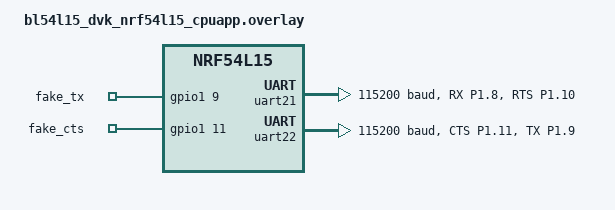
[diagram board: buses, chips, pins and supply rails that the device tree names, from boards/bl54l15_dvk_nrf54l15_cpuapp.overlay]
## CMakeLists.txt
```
# SPDX-License-Identifier: Apache-2.0

cmake_minimum_required(VERSION 3.28.0)

find_package(Zephyr REQUIRED HINTS $ENV{ZEPHYR_BASE})
project(uart_errors)

target_sources(app PRIVATE
    src/uart_errors_common.c
    src/test_parity.c
    src/test_stop_bit.c
    )
```

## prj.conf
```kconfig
CONFIG_SERIAL=y
CONFIG_GPIO=y
CONFIG_ZTEST=y
CONFIG_TEST_USERSPACE=y
CONFIG_UART_USE_RUNTIME_CONFIGURE=y
CONFIG_UART_INTERRUPT_DRIVEN=y
CONFIG_PM_DEVICE=y
```

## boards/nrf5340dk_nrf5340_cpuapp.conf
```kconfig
CONFIG_TIMING_FUNCTIONS=y
```

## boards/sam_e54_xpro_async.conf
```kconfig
CONFIG_DMA=y
```

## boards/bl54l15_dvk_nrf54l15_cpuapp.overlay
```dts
/*
 * Copyright (c) 2024 Nordic Semiconductor ASA
 * Copyright (c) 2025 Ezurio LLC
 *
 * SPDX-License-Identifier: Apache-2.0
 */

&pinctrl {
	uart21_default: uart21_default {
		group1 {
			psels = <NRF_PSEL(UART_RX, 1, 8)>,
				<NRF_PSEL(UART_RTS, 1, 10)>;
		};
	};

	uart21_sleep: uart21_sleep {
		group1 {
			psels = <NRF_PSEL(UART_RX, 1, 8)>,
				<NRF_PSEL(UART_RTS, 1, 10)>;
			low-power-enable;
		};
	};

	uart22_default: uart22_default {
		group1 {
			psels = <NRF_PSEL(UART_CTS, 1, 11)>;
			bias-pull-up;
		};

		group2 {
			psels = <NRF_PSEL(UART_TX, 1, 9)>;
		};
	};

	uart22_sleep: uart22_sleep {
		group1 {
			psels = <NRF_PSEL(UART_TX, 1, 9)>,
				<NRF_PSEL(UART_CTS, 1, 11)>;
			low-power-enable;
		};
	};
};

dut: &uart21 {
	current-speed = <115200>;
	pinctrl-0 = <&uart21_default>;
	pinctrl-1 = <&uart21_sleep>;
	pinctrl-names = "default", "sleep";
	status = "okay";
};

dut_aux: &uart22 {
	current-speed = <115200>;
	pinctrl-0 = <&uart22_default>;
	pinctrl-1 = <&uart22_sleep>;
	pinctrl-names = "default", "sleep";
	disable-rx;
	status = "okay";
};

/ {
	fake_uart {
		compatible = "gpio-keys";

		fake_tx: fake_tx {
			gpios = <&gpio1 9 GPIO_ACTIVE_HIGH>;
		};

		fake_cts: fake_cts {
			gpios = <&gpio1 11 GPIO_ACTIVE_HIGH>;
		};
	};
};
```

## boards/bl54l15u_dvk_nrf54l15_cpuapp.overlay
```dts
/*
 * Copyright (c) 2024 Nordic Semiconductor ASA
 * Copyright (c) 2025 Ezurio LLC
 *
 * SPDX-License-Identifier: Apache-2.0
 */

&pinctrl {
	uart21_default: uart21_default {
		group1 {
			psels = <NRF_PSEL(UART_RX, 1, 8)>,
				<NRF_PSEL(UART_RTS, 1, 10)>;
		};
	};

	uart21_sleep: uart21_sleep {
		group1 {
			psels = <NRF_PSEL(UART_RX, 1, 8)>,
				<NRF_PSEL(UART_RTS, 1, 10)>;
			low-power-enable;
		};
	};

	uart22_default: uart22_default {
		group1 {
			psels = <NRF_PSEL(UART_CTS, 1, 11)>;
			bias-pull-up;
		};

		group2 {
			psels = <NRF_PSEL(UART_TX, 1, 9)>;
		};
	};

	uart22_sleep: uart22_sleep {
		group1 {
			psels = <NRF_PSEL(UART_TX, 1, 9)>,
				<NRF_PSEL(UART_CTS, 1, 11)>;
			low-power-enable;
		};
	};
};

dut: &uart21 {
	status = "okay";
	current-speed = <115200>;
	pinctrl-0 = <&uart21_default>;
	pinctrl-1 = <&uart21_sleep>;
	pinctrl-names = "default", "sleep";
};

dut_aux: &uart22 {
	status = "okay";
	current-speed = <115200>;
	pinctrl-0 = <&uart22_default>;
	pinctrl-1 = <&uart22_sleep>;
	pinctrl-names = "default", "sleep";
	disable-rx;
};

/ {
	fake_uart {
		compatible = "gpio-keys";

		fake_tx: fake_tx {
			gpios = <&gpio1 9 GPIO_ACTIVE_HIGH>;
		};

		fake_cts: fake_cts {
			gpios = <&gpio1 11 GPIO_ACTIVE_HIGH>;
		};
	};
};
```

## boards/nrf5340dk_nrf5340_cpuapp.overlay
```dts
/* SPDX-License-Identifier: Apache-2.0 */

&pinctrl {
	uart1_default_alt: uart1_default_alt {
		group1 {
			psels = <NRF_PSEL(UART_RX, 0, 4)>;
			bias-pull-up;
		};

		group2 {
			psels = <NRF_PSEL(UART_RTS, 0, 6)>;
		};
	};

	uart1_sleep_alt: uart1_sleep_alt {
		group1 {
			psels = <NRF_PSEL(UART_RX, 0, 4)>,
				<NRF_PSEL(UART_RTS, 0, 6)>;
			low-power-enable;
		};
	};

	uart2_default_alt: uart2_default_alt {
		group1 {
			psels = <NRF_PSEL(UART_TX, 0, 5)>;
		};

		group2 {
			psels = <NRF_PSEL(UART_CTS, 0, 7)>;
			bias-pull-up;
		};
	};

	uart2_sleep_alt: uart2_sleep_alt {
		group1 {
			psels = <NRF_PSEL(UART_TX, 0, 5)>,
				<NRF_PSEL(UART_CTS, 0, 7)>;
			low-power-enable;
		};
	};
};

dut: &uart1 {
	compatible = "nordic,nrf-uarte";
	current-speed = <115200>;
	pinctrl-0 = <&uart1_default_alt>;
	pinctrl-1 = <&uart1_sleep_alt>;
	pinctrl-names = "default", "sleep";
	status = "okay";
};

dut_aux: &uart2 {
	compatible = "nordic,nrf-uarte";
	current-speed = <115200>;
	pinctrl-0 = <&uart2_default_alt>;
	pinctrl-1 = <&uart2_sleep_alt>;
	pinctrl-names = "default", "sleep";
	disable-rx;
	status = "okay";
};

/ {
	fake_uart {
		compatible = "gpio-keys";

		fake_tx: fake_tx {
			gpios = <&gpio0 5 GPIO_ACTIVE_HIGH>;
		};

		fake_cts: fake_cts {
			gpios = <&gpio0 7 GPIO_ACTIVE_HIGH>;
		};
	};
};
```

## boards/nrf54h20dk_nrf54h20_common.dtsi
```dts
/* SPDX-License-Identifier: Apache-2.0 */

&pinctrl {
	uart135_default_alt: uart135_default_alt {
		group1 {
			psels = <NRF_PSEL(UART_RX, 0, 6)>;
			bias-pull-up;
		};

		group2 {
			psels = <NRF_PSEL(UART_RTS, 0, 8)>;
		};
	};

	uart135_sleep_alt: uart135_sleep_alt {
		group1 {
			psels = <NRF_PSEL(UART_RX, 0, 6)>,
				<NRF_PSEL(UART_RTS, 0, 8)>;
			low-power-enable;
		};
	};
};

&pinctrl {
	uart137_default_alt: uart137_default_alt {
		group1 {
			psels = <NRF_PSEL(UART_TX, 0, 7)>;
		};

		group2 {
			psels = <NRF_PSEL(UART_CTS, 0, 9)>;
			bias-pull-up;
		};
	};

	uart137_sleep_alt: uart137_sleep_alt {
		group1 {
			psels = <NRF_PSEL(UART_TX, 0, 7)>,
				<NRF_PSEL(UART_CTS, 0, 9)>;
			low-power-enable;
		};
	};
};

&gpio0 {
	status = "okay";
};

dut: &uart135 {
	memory-regions = <&cpuapp_dma_region>;
	pinctrl-0 = <&uart135_default_alt>;
	pinctrl-1 = <&uart135_sleep_alt>;
	pinctrl-names = "default", "sleep";
	current-speed = <115200>;
	status = "okay";
};

dut_aux: &uart137 {
	memory-regions = <&cpuapp_dma_region>;
	pinctrl-0 = <&uart137_default_alt>;
	pinctrl-1 = <&uart137_sleep_alt>;
	pinctrl-names = "default", "sleep";
	current-speed = <115200>;
	disable-rx;
	status = "okay";
};

/ {
	fake_uart {
		compatible = "gpio-keys";

		fake_tx: fake_tx {
			gpios = <&gpio0 7 GPIO_ACTIVE_HIGH>;
		};

		fake_cts: fake_cts {
			gpios = <&gpio0 9 GPIO_ACTIVE_HIGH>;
		};
	};
};
```

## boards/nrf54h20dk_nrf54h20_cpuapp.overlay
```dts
/* SPDX-License-Identifier: Apache-2.0 */

#include "nrf54h20dk_nrf54h20_common.dtsi"

&dut_aux {
	memory-regions = <&cpuapp_dma_region>;
};

&dut {
	memory-regions = <&cpuapp_dma_region>;
};
```

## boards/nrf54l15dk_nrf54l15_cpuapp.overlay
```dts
/*
 * Copyright (c) 2025 Nordic Semiconductor ASA
 *
 * SPDX-License-Identifier: Apache-2.0
 */

&pinctrl {
	uart21_default: uart21_default {
		group1 {
			psels = <NRF_PSEL(UART_RX, 1, 8)>;
			bias-pull-up;
		};

		group2 {
			psels = <NRF_PSEL(UART_RTS, 1, 10)>;
		};
	};

	uart21_sleep: uart21_sleep {
		group1 {
			psels = <NRF_PSEL(UART_RX, 1, 8)>,
				<NRF_PSEL(UART_RTS, 1, 10)>;
			low-power-enable;
		};
	};

	uart22_default: uart22_default {
		group1 {
			psels = <NRF_PSEL(UART_CTS, 1, 11)>;
			bias-pull-up;
		};

		group2 {
			psels = <NRF_PSEL(UART_TX, 1, 9)>;
		};
	};

	uart22_sleep: uart22_sleep {
		group1 {
			psels = <NRF_PSEL(UART_CTS, 1, 11)>;
			low-power-enable;
		};
	};
};

dut: &uart21 {
	current-speed = <115200>;
	pinctrl-0 = <&uart21_default>;
	pinctrl-1 = <&uart21_sleep>;
	pinctrl-names = "default", "sleep";
	status = "okay";
};

dut_aux: &uart22 {
	current-speed = <115200>;
	pinctrl-0 = <&uart22_default>;
	pinctrl-1 = <&uart22_sleep>;
	pinctrl-names = "default", "sleep";
	disable-rx;
	status = "okay";
};

/ {
	fake_uart {
		compatible = "gpio-keys";

		fake_tx: fake_tx {
			gpios = <&gpio1 9 GPIO_ACTIVE_HIGH>;
		};

		fake_cts: fake_cts {
			gpios = <&gpio1 11 GPIO_ACTIVE_HIGH>;
		};
	};
};
```

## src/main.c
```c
/*
 * Copyright (c) 2024 Nordic Semiconductor ASA
 *
 * SPDX-License-Identifier: Apache-2.0
 */

/**
 * @addtogroup t_driver_uart
 * @{
 * @defgroup t_uart_errors test_uart_errors
 * @}
 */

#include <zephyr/drivers/uart.h>
#include <zephyr/pm/device.h>
#include <zephyr/pm/device_runtime.h>
#include <zephyr/ztest.h>
#include <zephyr/logging/log.h>
LOG_MODULE_REGISTER(test, LOG_LEVEL_NONE);

#if DT_NODE_EXISTS(DT_NODELABEL(dut))
#define UART_NODE DT_NODELABEL(dut)
#else
#error "No dut device in the test"
#endif

#if DT_NODE_EXISTS(DT_NODELABEL(dut_aux))
#define UART_NODE_AUX DT_NODELABEL(dut_aux)
#else
#error "No dut_aux device in the test"
#endif

static const struct device *const uart_dev = DEVICE_DT_GET(UART_NODE);
static const struct device *const uart_dev_aux = DEVICE_DT_GET(UART_NODE_AUX);

#define RX_CHUNK_CNT 2
#define RX_CHUNK_LEN 16
#define RX_TIMEOUT (1 * USEC_PER_MSEC)

static uint8_t rx_chunks[RX_CHUNK_CNT][16];
static uint32_t rx_chunks_mask = BIT_MASK(RX_CHUNK_CNT);
static uint8_t rx_buffer[256];
static uint32_t rx_buffer_cnt;
static volatile uint32_t rx_error_cnt;
static volatile bool rx_active;

struct aux_dut_data {
	const uint8_t *buf;
	size_t len;
	size_t curr;
	int err_byte;
	struct k_sem *sem;
	bool cfg_ok;
};

/* Simple buffer allocator. If allocation fails then test fails inside that function. */
static uint8_t *alloc_rx_chunk(void)
{
	uint32_t idx;

	zassert_true(rx_chunks_mask > 0);

	idx = __builtin_ctz(rx_chunks_mask);
	rx_chunks_mask &= ~BIT(idx);

	return rx_chunks[idx];
}

static void free_rx_chunk(uint8_t *buf)
{
	memset(buf, 0, RX_CHUNK_LEN);
	for (size_t i = 0; i < ARRAY_SIZE(rx_chunks); i++) {
		if (rx_chunks[i] == buf) {
			rx_chunks_mask |= BIT(i);
			break;
		}
	}
}

static void dut_async_callback(const struct device *dev, struct uart_event *evt, void *user_data)
{
	switch (evt->type) {
	case UART_TX_DONE:
		zassert_true(false);
		break;
	case UART_RX_RDY:
		LOG_INF("RX:%p len:%d off:%d",
			(void *)evt->data.rx.buf, evt->data.rx.len, evt->data.rx.offset);
		/* Aggregate all received data into a single buffer. */
		memcpy(&rx_buffer[rx_buffer_cnt], &evt->data.rx.buf[evt->data.rx.offset],
			evt->data.rx.len);
		rx_buffer_cnt += evt->data.rx.len;
		break;
	case UART_RX_BUF_REQUEST:
	{
		uint8_t *buf = alloc_rx_chunk();

		LOG_INF("buf request: %p", (void *)buf);
		zassert_equal(uart_rx_buf_rsp(dev, buf, RX_CHUNK_LEN), 0);
		break;
	}
	case UART_RX_BUF_RELEASED:
		LOG_INF("buf release: %p", (void *)evt->data.rx_buf.buf);
		free_rx_chunk(evt->data.rx_buf.buf);
		break;
	case UART_RX_DISABLED:
		zassert_true(rx_chunks_mask == BIT_MASK(RX_CHUNK_CNT));
		/* If test continues re-enable the receiver. Disabling may happen
		 * during the test after error is detected.
		 */
		if (rx_active) {
			uint8_t *buf = alloc_rx_chunk();
			int err;

			LOG_INF("RX disabled, re-enabling:%p", (void *)buf);
			err = uart_rx_enable(dev, buf, RX_CHUNK_LEN, RX_TIMEOUT);
			zassert_equal(err, 0);
		} else {
			LOG_WRN("RX disabled");
		}
		break;
	case UART_RX_ERROR:
		LOG_WRN("RX error");
		rx_error_cnt++;
		(void)uart_rx_disable(dev);
		break;
	default:
		zassert_true(false);
		break;
	}

}

static void dut_int_callback(const struct device *dev, void *user_data)
{
	while (true) {
		uart_irq_update(dev);

		if (uart_irq_is_pending(dev) <= 0) {
			break;
		}

		zassert_false(uart_irq_tx_ready(dev));
		if (uart_err_check(dev) != 0) {
			rx_error_cnt++;
		}
		if (uart_irq_rx_ready(dev)) {
			size_t rem = sizeof(rx_buffer) - rx_buffer_cnt;
			int len = uart_fifo_read(dev, &rx_buffer[rx_buffer_cnt], rem);

			zassert_true(len >= 0);
			rx_buffer_cnt += len;
		}
	}
}

static void aux_async_callback(const struct device *dev, struct uart_event *evt, void *user_data)
{
	struct k_sem *sem = user_data;

	switch (evt->type) {
	case UART_TX_DONE:
		k_sem_give(sem);
		break;
	default:
		zassert_true(false);
		break;
	}
}

/* Callback is handling injection of one corrupted byte. In order to corrupt that byte
 * uart must be reconfigured so when it is time to reconfigure interrupt is disabled
 * and semaphore is posted to reconfigure the uart in the thread context.
 */
static void aux_int_callback(const struct device *dev, void *user_data)
{
	struct aux_dut_data *data = user_data;
	size_t req_len;
	size_t tx_len;
	bool completed = data->curr == data->len;
	bool inject_err = data->err_byte >= 0;
	bool pre_err = inject_err && (data->curr == data->err_byte);
	bool post_err = inject_err && ((data->curr + 1) == data->err_byte);
	bool trig_reconfig = ((pre_err && data->cfg_ok) || (post_err && !data->cfg_ok));

	while (uart_irq_tx_ready(dev)) {
		if (completed || trig_reconfig) {
			/* Transmission completed or not configured correctly. */
			uart_irq_tx_disable(dev);
			k_sem_give(data->sem);
		} else {
			if (pre_err) {
				req_len = 1;
			} else if (inject_err && (data->curr < data->err_byte)) {
				req_len = data->err_byte - data->curr;
			} else {
				req_len = data->len - data->curr;
			}

			tx_len = uart_fifo_fill(dev, &data->buf[data->curr], req_len);
			data->curr += tx_len;
		}
	}
}

static void reconfigure(const struct device *dev, bool cfg_ok, bool *hwfc)
{
	struct uart_config config;

	zassert_equal(uart_config_get(uart_dev, &config), 0);

	if (hwfc) {
		if (IS_ENABLED(CONFIG_UART_INTERRUPT_DRIVEN)) {
			/* Reconfiguration may happen on disabled device. In the
			 * interrupt driven mode receiver is always on so we need
			 * to suspend the device to disable the receiver and
			 * reconfigure it.
			 */
			pm_device_action_run(dev, PM_DEVICE_ACTION_SUSPEND);
		}
		config.flow_ctrl = *hwfc ? UART_CFG_FLOW_CTRL_RTS_CTS : UART_CFG_FLOW_CTRL_NONE;
	}

	config.parity = cfg_ok ? UART_CFG_PARITY_NONE : UART_CFG_PARITY_EVEN;

	zassert_equal(uart_configure(dev, &config), 0);

	if (hwfc) {
		if (IS_ENABLED(CONFIG_UART_INTERRUPT_DRIVEN)) {
			pm_device_action_run(dev, PM_DEVICE_ACTION_RESUME);
		}
	}
}

/** @brief Transmit a buffer with optional one byte corrupted.
 *
 * Function supports asynchronous and interrupt driven APIs.
 *
 * @param dev Device.
 * @param buf Buffer.
 * @param len Buffer length.
 * @param err_byte Index of byte which is sent with parity enabled. -1 to send without error.
 */
static void aux_tx(const struct device *dev, const uint8_t *buf, size_t len, int err_byte)
{
	int err;
	struct k_sem sem;

	k_sem_init(&sem, 0, 1);

	if (IS_ENABLED(CONFIG_UART_INTERRUPT_DRIVEN)) {
		struct aux_dut_data data = {
			.buf = buf,
			.len = len,
			.err_byte = err_byte,
			.cfg_ok = true,
			.sem = &sem
		};

		err = uart_irq_callback_user_data_set(dev, aux_int_callback, &data);
		zassert_equal(err, 0);

		uart_irq_tx_enable(dev);

		if (err_byte >= 0) {
			/* Reconfigure to unaligned configuration. */
			err = k_sem_take(&sem, K_MSEC(100));
			zassert_equal(err, 0);
			data.cfg_ok = false;
			reconfigure(dev, false, NULL);
			uart_irq_tx_enable(dev);

			/* Reconfigure back to correct configuration. */
			err = k_sem_take(&sem, K_MSEC(100));
			zassert_equal(err, 0);
			data.cfg_ok = true;
			reconfigure(dev, true, NULL);
			uart_irq_tx_enable(dev);
		}

		/* Wait for completion. */
		err = k_sem_take(&sem, K_MSEC(100));
		zassert_equal(err, 0);
		return;
	}

	err = uart_callback_set(dev, aux_async_callback, &sem);
	zassert_equal(err, 0);

	if (err_byte < 0) {
		err = uart_tx(dev, buf, len, 100 * USEC_PER_MSEC);
		zassert_equal(err, 0);

		err = k_sem_take(&sem, K_MSEC(100));
		zassert_equal(err, 0);
		return;
	} else if (err_byte > 0) {
		err = uart_tx(dev, buf, err_byte, 100 * USEC_PER_MSEC);
		zassert_equal(err, 0);

		err = k_sem_take(&sem, K_MSEC(100));
		zassert_equal(err, 0);
	}
	/* Reconfigure to unaligned configuration that will lead to error. */
	reconfigure(dev, false, NULL);

	err = uart_tx(dev, &buf[err_byte], 1, 100 * USEC_PER_MSEC);
	zassert_equal(err, 0);

	err = k_sem_take(&sem, K_MSEC(100));
	zassert_equal(err, 0);
	/* Reconfigure back to the correct configuration. */
	reconfigure(dev, true, NULL);

	err = uart_tx(dev, &buf[err_byte + 1], len - err_byte - 1, 100 * USEC_PER_MSEC);
	zassert_equal(err, 0);

	err = k_sem_take(&sem, K_MSEC(100));
	zassert_equal(err, 0);
}

/** @brief Test function.
 *
 * Test starts by sending 10 bytes without error then 10 bytes with an error on
 * @p err_byte and then again 10 bytes without error. It is expected that driver
 * will receive correctly first 10 bytes then detect error and recover to
 * receive correctly last 10 bytes.
 *
 * @param hwfc Use hardware flow control.
 * @param err_byte Index of corrupted byte in the second 10 byte sequence.
 */
static void test_detect_error(bool hwfc, int err_byte)
{
	uint8_t buf[10];
	int err;

	reconfigure(uart_dev, true, &hwfc);
	reconfigure(uart_dev_aux, true, &hwfc);

	for (size_t i = 0; i < sizeof(buf); i++) {
		buf[i] = i;
	}

	if (IS_ENABLED(CONFIG_UART_INTERRUPT_DRIVEN)) {
		if (IS_ENABLED(CONFIG_PM_DEVICE_RUNTIME)) {
			pm_device_runtime_get(uart_dev);
		}
		uart_irq_err_enable(uart_dev);
		uart_irq_rx_enable(uart_dev);
	} else {
		uint8_t *b = alloc_rx_chunk();

		LOG_INF("dut rx enable buf:%p", (void *)b);
		err = uart_rx_enable(uart_dev, b, RX_CHUNK_LEN, RX_TIMEOUT);
		zassert_equal(err, 0);
	}

	/* Send TX without error */
	aux_tx(uart_dev_aux, buf, sizeof(buf), -1);
	/* Send TX without error */

	k_msleep(10);
	zassert_equal(sizeof(buf), rx_buffer_cnt, "Expected %d got %d", sizeof(buf), rx_buffer_cnt);
	zassert_equal(memcmp(buf, rx_buffer, rx_buffer_cnt), 0);

	/* Send TX with error on nth byte. */
	aux_tx(uart_dev_aux, buf, sizeof(buf), err_byte);

	/* At this point when error is detected receiver will be restarted and it may
	 * be started when there is a transmission on the line if HWFC is disabled
	 * which will trigger next error so until there is a gap on the line there
	 * might be multiple errors detected. However, when HWFC is enabled then there
	 * should be only one error.
	 */
	k_msleep(100);
	zassert_true(rx_error_cnt > 0);

	/* Send TX without error. Receiver is settled so it should be correctly received. */
	aux_tx(uart_dev_aux, buf, sizeof(buf), -1);

	k_msleep(100);
	TC_PRINT("RX bytes:%d/%d err_cnt:%d\n", rx_buffer_cnt, 3 * sizeof(buf), rx_error_cnt);

	LOG_HEXDUMP_INF(rx_buffer, rx_buffer_cnt, "Received data:");

	/* Last received chunk should be correct. */
	zassert_equal(memcmp(buf, &rx_buffer[rx_buffer_cnt - sizeof(buf)], sizeof(buf)), 0);

	if (IS_ENABLED(CONFIG_UART_INTERRUPT_DRIVEN)) {
		uart_irq_err_disable(uart_dev);
		uart_irq_rx_disable(uart_dev);
		if (IS_ENABLED(CONFIG_PM_DEVICE_RUNTIME)) {
			pm_device_runtime_put(uart_dev);
		}
	} else {
		rx_active = false;
		err = uart_rx_disable(uart_dev);
		zassert_true((err == 0) || (err == -EFAULT));

		k_msleep(10);
	}
}

ZTEST(uart_errors, test_detect_error_first_byte)
{
	test_detect_error(false, 0);
}

ZTEST(uart_errors, test_detect_error_in_the_middle)
{
	test_detect_error(false, 5);
}

ZTEST(uart_errors, test_detect_error_first_byte_hwfc)
{
	test_detect_error(true, 0);
}

ZTEST(uart_errors, test_detect_error_in_the_middle_hwfc)
{
	test_detect_error(true, 5);
}

/*
 * Test setup
 */
static void *test_setup(void)
{
	zassert_true(device_is_ready(uart_dev), "DUT UART device is not ready");
	zassert_true(device_is_ready(uart_dev_aux), "DUT_AUX UART device is not ready");

	if (IS_ENABLED(CONFIG_UART_INTERRUPT_DRIVEN)) {
		zassert_equal(uart_irq_callback_set(uart_dev, dut_int_callback), 0);
	} else {
		zassert_equal(uart_callback_set(uart_dev, dut_async_callback, NULL), 0);
	}

	return NULL;
}

static void before(void *unused)
{
	ARG_UNUSED(unused);
	rx_buffer_cnt = 0;
	rx_error_cnt = 0;
	rx_active = true;
}

ZTEST_SUITE(uart_errors, NULL, test_setup, before, NULL, NULL);
```

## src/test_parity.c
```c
/*
 * Copyright (c) 2026 Nordic Semiconductor ASA
 *
 * SPDX-License-Identifier: Apache-2.0
 */

#include "uart_errors_common.h"

#include <zephyr/ztest.h>
#include <zephyr/logging/log.h>

LOG_MODULE_DECLARE(uart_errors, LOG_LEVEL_NONE);

static void aux_tx_parity_error(const struct device *dev, const uint8_t *buf, size_t len,
				int err_byte, enum uart_config_parity err_parity,
				enum uart_config_parity ok_parity)
{
	struct k_sem sem;
	int err;

	k_sem_init(&sem, 0, 1);

#if IS_ENABLED(CONFIG_UART_INTERRUPT_DRIVEN)
	{
		struct parity_error_tx_data data = {
			.buf = buf,
			.len = len,
			.err_byte = err_byte,
			.cfg_ok = true,
			.sem = &sem,
		};

		err = uart_irq_callback_user_data_set(dev, parity_error_tx_int_callback, &data);
		zassert_equal(err, 0);
		uart_irq_tx_enable(dev);

		if (err_byte >= 0) {
			zassert_equal(k_sem_take(&sem, K_MSEC(100)), 0);
			data.cfg_ok = false;
			reconfigure(dev, err_parity, true, false, false, NULL);
			uart_irq_tx_enable(dev);

			zassert_equal(k_sem_take(&sem, K_MSEC(100)), 0);
			data.cfg_ok = true;
			reconfigure(dev, ok_parity, true, false, false, NULL);
			uart_irq_tx_enable(dev);
		}

		zassert_equal(k_sem_take(&sem, K_MSEC(100)), 0);
	}
#elif IS_ENABLED(CONFIG_UART_ASYNC_API)
	err = uart_callback_set(dev, aux_async_callback, &sem);
	zassert_equal(err, 0);

	if (err_byte > 0) {
		zassert_equal(uart_tx(dev, buf, err_byte, 100 * USEC_PER_MSEC), 0);
		zassert_equal(k_sem_take(&sem, K_MSEC(100)), 0);
	}

	reconfigure(dev, err_parity, true, false, false, NULL);
	zassert_equal(uart_callback_set(dev, aux_async_callback, &sem), 0);
	zassert_equal(uart_tx(dev, &buf[err_byte], 1, 100 * USEC_PER_MSEC), 0);
	zassert_equal(k_sem_take(&sem, K_MSEC(100)), 0);

	reconfigure(dev, ok_parity, true, false, false, NULL);
	zassert_equal(uart_callback_set(dev, aux_async_callback, &sem), 0);
	zassert_equal(uart_tx(dev, &buf[err_byte + 1], len - err_byte - 1, 100 * USEC_PER_MSEC), 0);
	zassert_equal(k_sem_take(&sem, K_MSEC(100)), 0);
#endif
}

static void test_detect_parity_type_error(bool hwfc, int err_byte,
					  enum uart_config_parity rx_parity,
					  enum uart_config_parity tx_err_parity)
{
	uint8_t buf[10];

	for (size_t i = 0; i < sizeof(buf); i++) {
		buf[i] = i;
	}

	start_receiver(hwfc, rx_parity, false);

	aux_tx(uart_dev_aux, buf, sizeof(buf));
	k_msleep(10);
	zassert_equal(sizeof(buf), rx_buffer_cnt);
	zassert_equal(memcmp(buf, rx_buffer, sizeof(buf)), 0);

	aux_tx_parity_error(uart_dev_aux, buf, sizeof(buf), err_byte, tx_err_parity, rx_parity);

	k_msleep(10);
	zassert_true(rx_parity_err_cnt > 0);

	aux_tx(uart_dev_aux, buf, sizeof(buf));
	k_msleep(10);

	TC_PRINT("RX bytes:%d/%d rx_stopped:%u parity_err:%u framing_err:%u\n", rx_buffer_cnt,
		 3 * (int)sizeof(buf), rx_stopped_cnt, rx_parity_err_cnt, rx_framing_err_cnt);
	zassert_equal(memcmp(buf, &rx_buffer[rx_buffer_cnt - sizeof(buf)], sizeof(buf)), 0);

	receiver_shutdown();
}

/* clang-format off */
#define PARITY_ZTEST(_name, _hwfc, _err_byte, _rx_parity, _tx_err_parity) \
	ZTEST(uart_errors_parity, test_##_name) \
	{ \
		test_detect_parity_type_error(_hwfc, _err_byte, _rx_parity, _tx_err_parity); \
	}
/* clang-format on */

PARITY_ZTEST(detect_parity_even_error_first_byte, false, 0, UART_CFG_PARITY_ODD,
	     UART_CFG_PARITY_EVEN)
PARITY_ZTEST(detect_parity_even_error_in_the_middle, false, 5, UART_CFG_PARITY_ODD,
	     UART_CFG_PARITY_EVEN)
PARITY_ZTEST(detect_parity_even_error_first_byte_hwfc, true, 0, UART_CFG_PARITY_ODD,
	     UART_CFG_PARITY_EVEN)
PARITY_ZTEST(detect_parity_even_error_in_the_middle_hwfc, true, 5, UART_CFG_PARITY_ODD,
	     UART_CFG_PARITY_EVEN)

PARITY_ZTEST(detect_parity_odd_error_first_byte, false, 0, UART_CFG_PARITY_EVEN,
	     UART_CFG_PARITY_ODD)
PARITY_ZTEST(detect_parity_odd_error_in_the_middle, false, 5, UART_CFG_PARITY_EVEN,
	     UART_CFG_PARITY_ODD)
PARITY_ZTEST(detect_parity_odd_error_first_byte_hwfc, true, 0, UART_CFG_PARITY_EVEN,
	     UART_CFG_PARITY_ODD)
PARITY_ZTEST(detect_parity_odd_error_in_the_middle_hwfc, true, 5, UART_CFG_PARITY_EVEN,
	     UART_CFG_PARITY_ODD)

PARITY_ZTEST(detect_parity_none_error_first_byte, false, 0, UART_CFG_PARITY_EVEN,
	     UART_CFG_PARITY_NONE)
PARITY_ZTEST(detect_parity_none_error_in_the_middle, false, 5, UART_CFG_PARITY_EVEN,
	     UART_CFG_PARITY_NONE)
PARITY_ZTEST(detect_parity_none_error_first_byte_hwfc, true, 0, UART_CFG_PARITY_EVEN,
	     UART_CFG_PARITY_NONE)
PARITY_ZTEST(detect_parity_none_error_in_the_middle_hwfc, true, 5, UART_CFG_PARITY_EVEN,
	     UART_CFG_PARITY_NONE)

ZTEST_SUITE(uart_errors_parity, NULL, test_setup, test_before, test_after, NULL);
```

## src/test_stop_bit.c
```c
/*
 * Copyright (c) 2026 Nordic Semiconductor ASA
 *
 * SPDX-License-Identifier: Apache-2.0
 */

#include "uart_errors_common.h"

#include <zephyr/device.h>
#include <zephyr/drivers/gpio.h>
#include <zephyr/kernel.h>
#include <zephyr/pm/device.h>
#include <zephyr/timing/timing.h>
#include <zephyr/ztest.h>
#include <zephyr/logging/log.h>

LOG_MODULE_DECLARE(uart_errors, LOG_LEVEL_NONE);

#if DT_NODE_EXISTS(DT_NODELABEL(fake_tx))
static const struct gpio_dt_spec fake_tx = GPIO_DT_SPEC_GET(DT_NODELABEL(fake_tx), gpios);
#define HAS_FAKE_TX 1
#else
#define HAS_FAKE_TX 0
#endif

#if DT_NODE_EXISTS(DT_NODELABEL(fake_cts))
static const struct gpio_dt_spec fake_cts = GPIO_DT_SPEC_GET(DT_NODELABEL(fake_cts), gpios);
#define HAS_FAKE_CTS 1
#else
#define HAS_FAKE_CTS 0
#endif

#if HAS_FAKE_TX

#if IS_ENABLED(CONFIG_TIMING_FUNCTIONS)
static bool use_timing;
static timing_t timing_t0;
#endif

static uint32_t tx_cycle_get(void)
{
#if IS_ENABLED(CONFIG_TIMING_FUNCTIONS)
	if (use_timing) {
		timing_t now = timing_counter_get();

		return (uint32_t)timing_cycles_get(&timing_t0, &now);
	}
#endif

	return k_cycle_get_32();
}

static uint32_t bit_time_cycles(uint32_t baudrate)
{
	uint32_t bit_cycles = (sys_clock_hw_cycles_per_sec() + baudrate / 2U) / baudrate;

#if IS_ENABLED(CONFIG_TIMING_FUNCTIONS)
	use_timing = (bit_cycles == 0U);
	if (use_timing) {
		timing_init();
		timing_start();
		timing_t0 = timing_counter_get();
		bit_cycles = (timing_freq_get() + baudrate / 2U) / baudrate;
	}
#endif

	return bit_cycles;
}

static void fake_tx_takeover(void)
{
	zassert_equal(gpio_pin_configure_dt(&fake_tx, GPIO_OUTPUT_HIGH), 0);
	zassert_equal(gpio_pin_set_dt(&fake_tx, 1), 0);
}

static void fake_tx_hold_bit(int level, uint32_t *next, uint32_t bit_cycles)
{
	while ((int32_t)(tx_cycle_get() - *next) < 0) {
	}

	zassert_equal(gpio_pin_set_dt(&fake_tx, level), 0);
	*next += bit_cycles;
}

static void gpio_send_uart_frame(uint8_t byte, bool two_stop_bits, bool stop0_bad, bool stop1_bad,
				 uint32_t *next, uint32_t bit_cycles)
{
	/* An ISR or CTS wait ran past the start bit edge, restart the timeline. */
	if ((int32_t)(tx_cycle_get() - *next) > 0) {
		*next = tx_cycle_get();
	}

	fake_tx_hold_bit(0, next, bit_cycles);

	for (unsigned int i = 0; i < 8U; i++) {
		fake_tx_hold_bit((byte >> i) & 0x1, next, bit_cycles);
	}

	fake_tx_hold_bit(stop0_bad ? 0 : 1, next, bit_cycles);

	if (two_stop_bits) {
		fake_tx_hold_bit(stop1_bad ? 0 : 1, next, bit_cycles);
	}

	/* Receiver needs an idle high level to resync after a low stop bit. */
	if (stop0_bad || stop1_bad) {
		fake_tx_hold_bit(1, next, bit_cycles);
		fake_tx_hold_bit(1, next, bit_cycles);
	}
}

#if HAS_FAKE_CTS
static bool fake_cts_clear(void)
{
	int val = gpio_pin_get_dt(&fake_cts);

	return val == 0;
}

static void fake_cts_wait_clear(void)
{
	unsigned int retries = 100000;

	while (!fake_cts_clear()) {
		k_busy_wait(1);
		zassert_true(retries-- > 0, "Timeout waiting for CTS");
	}
}
#endif /* HAS_FAKE_CTS */

static bool aux_line_release(void)
{
	int err;

#if IS_ENABLED(CONFIG_UART_INTERRUPT_DRIVEN)
	uart_irq_tx_disable(uart_dev_aux);
#endif

	zassert_true(IS_ENABLED(CONFIG_PM_DEVICE));

	do {
		err = pm_device_action_run(uart_dev_aux, PM_DEVICE_ACTION_SUSPEND);
		if (err == -EAGAIN) {
			k_busy_wait(1);
		}
	} while (err == -EAGAIN);
	/* -EALREADY means that runtime PM has already suspended the device. */
	zassert_true(err == 0 || err == -EALREADY);

	fake_tx_takeover();

	return err == 0;
}

static void aux_line_resume(bool suspended)
{
	if (suspended) {
		zassert_equal(pm_device_action_run(uart_dev_aux, PM_DEVICE_ACTION_RESUME), 0);
	}
}

/*
 * The whole buffer is bit-banged, so UART and GPIO switch over only on the idle
 * line and the frames, including the bad one, are sent back-to-back.
 */
static void aux_tx_stop_bit_error(const uint8_t *buf, size_t len, int err_byte, bool two_stop_bits,
				  bool stop0_bad, bool stop1_bad, bool hwfc)
{
	struct uart_config cfg;
	uint32_t bit_cycles;
	uint32_t next;
	bool suspended;

	zassert_equal(uart_config_get(uart_dev, &cfg), 0);
	zassert_true(gpio_is_ready_dt(&fake_tx));

	bit_cycles = bit_time_cycles(cfg.baudrate);
	zassert_not_equal(bit_cycles, 0U, "Timer too slow, enable CONFIG_TIMING_FUNCTIONS");

	suspended = aux_line_release();
#if HAS_FAKE_CTS
	if (hwfc) {
		zassert_equal(gpio_pin_configure_dt(&fake_cts, GPIO_INPUT), 0);
	}
#endif

	next = tx_cycle_get();
	for (size_t i = 0; i < len; i++) {
		bool err = (i == (size_t)err_byte);

#if HAS_FAKE_CTS
		if (hwfc) {
			fake_cts_wait_clear();
		}
#endif

		gpio_send_uart_frame(buf[i], two_stop_bits, err && stop0_bad, err && stop1_bad,
				     &next, bit_cycles);
	}

	while ((int32_t)(tx_cycle_get() - next) < 0) {
	}

	aux_line_resume(suspended);
}

static bool two_stop_bits_supported(void)
{
	struct uart_config cfg;

	if (uart_config_get(uart_dev, &cfg) != 0) {
		return false;
	}

	cfg.parity = UART_CFG_PARITY_NONE;
	cfg.stop_bits = UART_CFG_STOP_BITS_2;

	return uart_configure(uart_dev, &cfg) == 0;
}

static void stop_bit_ztest_skip_if_unavailable(bool hwfc, bool two_stop_bits)
{
	if (!gpio_is_ready_dt(&fake_tx)) {
		ztest_test_skip();
	}

#if HAS_FAKE_CTS
	if (hwfc && !gpio_is_ready_dt(&fake_cts)) {
		ztest_test_skip();
	}
#else
	if (hwfc) {
		ztest_test_skip();
	}
#endif

	if (two_stop_bits && !two_stop_bits_supported()) {
		ztest_test_skip();
	}
}

static void test_detect_stop_bit_error(bool hwfc, int err_byte, bool two_stop_bits, bool stop0_bad,
				       bool stop1_bad)
{
	uint8_t buf[10];
	uint32_t framing_before;

	for (size_t i = 0; i < sizeof(buf); i++) {
		buf[i] = i;
	}

	start_receiver(hwfc, UART_CFG_PARITY_NONE, two_stop_bits);

	aux_tx(uart_dev_aux, buf, sizeof(buf));
	k_msleep(10);
	zassert_equal(sizeof(buf), rx_buffer_cnt);
	zassert_equal(memcmp(buf, rx_buffer, sizeof(buf)), 0);

	framing_before = rx_framing_err_cnt;
	aux_tx_stop_bit_error(buf, sizeof(buf), err_byte, two_stop_bits, stop0_bad, stop1_bad,
			      hwfc);

	k_msleep(10);
	zassert_true(rx_framing_err_cnt > framing_before);

	aux_tx(uart_dev_aux, buf, sizeof(buf));
	k_msleep(10);

	TC_PRINT("RX bytes:%d/%d rx_stopped:%u parity_err:%u framing_err:%u\n", rx_buffer_cnt,
		 3 * (int)sizeof(buf), rx_stopped_cnt, rx_parity_err_cnt, rx_framing_err_cnt);

	zassert_equal(memcmp(buf, &rx_buffer[rx_buffer_cnt - sizeof(buf)], sizeof(buf)), 0);

	receiver_shutdown();
}

/* clang-format off */
#define STOP_BIT_ZTEST(_name, _hwfc, _err_byte, _two_stop, _s0_bad, _s1_bad) \
	ZTEST(uart_errors_stop_bit, test_##_name) \
	{ \
		stop_bit_ztest_skip_if_unavailable(_hwfc, _two_stop); \
		test_detect_stop_bit_error(_hwfc, _err_byte, _two_stop, _s0_bad, _s1_bad); \
	}
/* clang-format on */

STOP_BIT_ZTEST(detect_stop_bit_error_1_0_first_byte, false, 0, false, true, false)
STOP_BIT_ZTEST(detect_stop_bit_error_1_0_in_the_middle, false, 5, false, true, false)
STOP_BIT_ZTEST(detect_stop_bit_error_1_0_first_byte_hwfc, true, 0, false, true, false)
STOP_BIT_ZTEST(detect_stop_bit_error_1_0_in_the_middle_hwfc, true, 5, false, true, false)

STOP_BIT_ZTEST(detect_stop_bit_error_2_00_first_byte, false, 0, true, true, true)
STOP_BIT_ZTEST(detect_stop_bit_error_2_00_in_the_middle, false, 5, true, true, true)
STOP_BIT_ZTEST(detect_stop_bit_error_2_00_first_byte_hwfc, true, 0, true, true, true)
STOP_BIT_ZTEST(detect_stop_bit_error_2_00_in_the_middle_hwfc, true, 5, true, true, true)

STOP_BIT_ZTEST(detect_stop_bit_error_2_01_first_byte, false, 0, true, true, false)
STOP_BIT_ZTEST(detect_stop_bit_error_2_01_in_the_middle, false, 5, true, true, false)
STOP_BIT_ZTEST(detect_stop_bit_error_2_01_first_byte_hwfc, true, 0, true, true, false)
STOP_BIT_ZTEST(detect_stop_bit_error_2_01_in_the_middle_hwfc, true, 5, true, true, false)

STOP_BIT_ZTEST(detect_stop_bit_error_2_10_first_byte, false, 0, true, false, true)
STOP_BIT_ZTEST(detect_stop_bit_error_2_10_in_the_middle, false, 5, true, false, true)
STOP_BIT_ZTEST(detect_stop_bit_error_2_10_first_byte_hwfc, true, 0, true, false, true)
STOP_BIT_ZTEST(detect_stop_bit_error_2_10_in_the_middle_hwfc, true, 5, true, false, true)

#endif /* HAS_FAKE_TX */

ZTEST_SUITE(uart_errors_stop_bit, NULL, test_setup, test_before, test_after, NULL);
```

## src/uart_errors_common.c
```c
/*
 * Copyright (c) 2026 Nordic Semiconductor ASA
 *
 * SPDX-License-Identifier: Apache-2.0
 */

#include "uart_errors_common.h"

#include <zephyr/pm/device.h>
#include <zephyr/pm/device_runtime.h>
#include <zephyr/ztest.h>
#include <zephyr/logging/log.h>

LOG_MODULE_REGISTER(uart_errors, LOG_LEVEL_NONE);

#if DT_NODE_EXISTS(DT_NODELABEL(dut))
#define UART_NODE DT_NODELABEL(dut)
#else
#error "No dut device in the test"
#endif

#if DT_NODE_EXISTS(DT_NODELABEL(dut_aux))
#define UART_NODE_AUX DT_NODELABEL(dut_aux)
#else
#error "No dut_aux device in the test"
#endif

const struct device *const uart_dev = DEVICE_DT_GET(UART_NODE);
const struct device *const uart_dev_aux = DEVICE_DT_GET(UART_NODE_AUX);

#define RX_CHUNK_CNT 2
#define RX_CHUNK_LEN 16
#define RX_TIMEOUT   (1 * USEC_PER_MSEC)

uint8_t rx_buffer[256];
uint32_t rx_buffer_cnt;
volatile uint32_t rx_stopped_cnt;
volatile uint32_t rx_parity_err_cnt;
volatile uint32_t rx_framing_err_cnt;
volatile bool rx_active;

#if IS_ENABLED(CONFIG_UART_ASYNC_API)
static uint8_t rx_chunks[RX_CHUNK_CNT][RX_CHUNK_LEN];
static uint32_t rx_chunks_mask = BIT_MASK(RX_CHUNK_CNT);

static uint8_t *alloc_rx_chunk(void)
{
	uint32_t idx;

	if (rx_chunks_mask == 0) {
		return NULL;
	}

	idx = __builtin_ctz(rx_chunks_mask);
	rx_chunks_mask &= ~BIT(idx);

	return rx_chunks[idx];
}

static void free_rx_chunk(uint8_t *buf)
{
	for (size_t i = 0; i < ARRAY_SIZE(rx_chunks); i++) {
		if (rx_chunks[i] == buf) {
			rx_chunks_mask |= BIT(i);
			return;
		}
	}
}
#endif /* CONFIG_UART_ASYNC_API */

static void note_rx_error(int err)
{
	rx_stopped_cnt++;

	if (err & UART_ERROR_PARITY) {
		rx_parity_err_cnt++;
	}
	if (err & UART_ERROR_FRAMING) {
		rx_framing_err_cnt++;
	}
}

void uart_pair_configure(bool hwfc, enum uart_config_parity parity, bool two_stop_bits)
{
	reconfigure(uart_dev, parity, true, two_stop_bits, true, &hwfc);
	reconfigure(uart_dev_aux, parity, true, two_stop_bits, true, &hwfc);
}

#if IS_ENABLED(CONFIG_UART_ASYNC_API)
static void dut_async_callback(const struct device *dev, struct uart_event *evt, void *user_data)
{
	ARG_UNUSED(user_data);

	switch (evt->type) {
	case UART_TX_DONE:
		zassert_true(false);
		break;
	case UART_RX_RDY:
		LOG_INF("RX:%p len:%d off:%d", (void *)evt->data.rx.buf, evt->data.rx.len,
			evt->data.rx.offset);
		memcpy(&rx_buffer[rx_buffer_cnt], &evt->data.rx.buf[evt->data.rx.offset],
		       evt->data.rx.len);
		rx_buffer_cnt += evt->data.rx.len;
		break;
	case UART_RX_BUF_REQUEST: {
		uint8_t *buf = alloc_rx_chunk();

		LOG_INF("buf request: %p", (void *)buf);
		zassert_equal(uart_rx_buf_rsp(dev, buf, RX_CHUNK_LEN), 0);
		break;
	}
	case UART_RX_BUF_RELEASED:
		LOG_INF("buf release: %p", (void *)evt->data.rx_buf.buf);
		free_rx_chunk(evt->data.rx_buf.buf);
		break;
	case UART_RX_DISABLED:
		zassert_true(rx_chunks_mask == BIT_MASK(RX_CHUNK_CNT));
		if (rx_active) {
			uint8_t *buf = alloc_rx_chunk();
			int err;

			LOG_INF("RX disabled, re-enabling:%p", (void *)buf);
			err = uart_rx_enable(dev, buf, RX_CHUNK_LEN, RX_TIMEOUT);
			zassert_equal(err, 0);
		} else {
			LOG_WRN("RX disabled");
		}
		break;
	case UART_RX_STOPPED:
		LOG_WRN("RX error");
		note_rx_error(evt->data.rx_stop.reason);
		break;
	default:
		zassert_true(false);
		break;
	}
}

void aux_async_callback(const struct device *dev, struct uart_event *evt, void *user_data)
{
	ARG_UNUSED(dev);

	if (evt->type == UART_TX_DONE) {
		k_sem_give(user_data);
	}
}
#endif /* CONFIG_UART_ASYNC_API */

#if IS_ENABLED(CONFIG_UART_INTERRUPT_DRIVEN)
static void dut_int_callback(const struct device *dev, void *user_data)
{
	ARG_UNUSED(user_data);

	while (uart_irq_update(dev), uart_irq_is_pending(dev) > 0) {
		int err = uart_err_check(dev);
		int len;

		zassert_false(uart_irq_tx_ready(dev));

		if (err != 0) {
			note_rx_error(err);
		}

		if (!uart_irq_rx_ready(dev)) {
			continue;
		}

		len = uart_fifo_read(dev, &rx_buffer[rx_buffer_cnt],
				     sizeof(rx_buffer) - rx_buffer_cnt);
		zassert_true(len >= 0);
		rx_buffer_cnt += len;
	}
}

void parity_error_tx_int_callback(const struct device *dev, void *user_data)
{
	struct parity_error_tx_data *data = user_data;
	size_t req_len;
	size_t tx_len;
	bool error_inject = data->err_byte >= 0;

	while (uart_irq_tx_ready(dev)) {
		bool completed = data->curr == data->len;
		bool pre_err = error_inject && (data->curr == data->err_byte);
		bool post_err = error_inject && (data->curr == (data->err_byte + 1));
		bool trig_reconfig = ((pre_err && data->cfg_ok) || (post_err && !data->cfg_ok));

		if (completed || trig_reconfig) {
			uart_irq_tx_disable(dev);
			k_sem_give(data->sem);
			break;
		}

		if (pre_err) {
			req_len = 1;
		} else if (error_inject && (data->curr < data->err_byte)) {
			req_len = data->err_byte - data->curr;
		} else {
			req_len = data->len - data->curr;
		}

		tx_len = uart_fifo_fill(dev, &data->buf[data->curr], req_len);
		data->curr += tx_len;
	}
}
#endif /* CONFIG_UART_INTERRUPT_DRIVEN */

void reconfigure(const struct device *dev, enum uart_config_parity parity, bool set_parity,
		 bool two_stop_bits, bool set_stop_bits, bool *hwfc)
{
	struct uart_config config;

	zassert_equal(uart_config_get(dev, &config), 0);

	if (hwfc) {
#if IS_ENABLED(CONFIG_UART_INTERRUPT_DRIVEN) && IS_ENABLED(CONFIG_PM_DEVICE)
		pm_device_action_run(dev, PM_DEVICE_ACTION_SUSPEND);
#endif
		config.flow_ctrl = *hwfc ? UART_CFG_FLOW_CTRL_RTS_CTS : UART_CFG_FLOW_CTRL_NONE;
	}

	if (set_parity) {
		config.parity = parity;
	}

	if (set_stop_bits) {
		config.stop_bits = two_stop_bits ? UART_CFG_STOP_BITS_2 : UART_CFG_STOP_BITS_1;
	}

	zassert_equal(uart_configure(dev, &config), 0);

#if IS_ENABLED(CONFIG_UART_INTERRUPT_DRIVEN) && IS_ENABLED(CONFIG_PM_DEVICE)
	if (hwfc) {
		pm_device_action_run(dev, PM_DEVICE_ACTION_RESUME);
	}
#endif
}

void aux_tx(const struct device *dev, const uint8_t *buf, size_t len)
{
	struct k_sem sem;
	int err;

	k_sem_init(&sem, 0, 1);

#if IS_ENABLED(CONFIG_UART_INTERRUPT_DRIVEN)
	{
		struct parity_error_tx_data data = {
			.buf = buf,
			.len = len,
			.err_byte = -1,
			.cfg_ok = true,
			.sem = &sem,
		};

		err = uart_irq_callback_user_data_set(dev, parity_error_tx_int_callback, &data);
		zassert_equal(err, 0);
		uart_irq_tx_enable(dev);
	}
#elif IS_ENABLED(CONFIG_UART_ASYNC_API)
	err = uart_callback_set(dev, aux_async_callback, &sem);
	zassert_equal(err, 0);
	err = uart_tx(dev, buf, len, 100 * USEC_PER_MSEC);
	zassert_equal(err, 0);
#endif

	zassert_equal(k_sem_take(&sem, K_MSEC(100)), 0);
}

void reset_rx_state(void)
{
	rx_buffer_cnt = 0;
	rx_stopped_cnt = 0;
	rx_parity_err_cnt = 0;
	rx_framing_err_cnt = 0;
	rx_active = false;
#if IS_ENABLED(CONFIG_UART_ASYNC_API)
	rx_chunks_mask = BIT_MASK(RX_CHUNK_CNT);
#endif
}

void receiver_shutdown(void)
{
#if IS_ENABLED(CONFIG_UART_INTERRUPT_DRIVEN)
	uart_irq_err_disable(uart_dev);
	uart_irq_rx_disable(uart_dev);
#if IS_ENABLED(CONFIG_PM_DEVICE_RUNTIME)
	pm_device_runtime_put(uart_dev);
#endif
#elif IS_ENABLED(CONFIG_UART_ASYNC_API)
	int err;

	rx_active = false;
	err = uart_rx_disable(uart_dev);
	if (err == 0 || err == -EFAULT) {
		k_msleep(10);
	}
	async_rx_reclaim_chunks();
#endif
}

#if IS_ENABLED(CONFIG_UART_ASYNC_API)
void async_rx_reclaim_chunks(void)
{
	unsigned int retries = 100;

	while (rx_chunks_mask != BIT_MASK(RX_CHUNK_CNT) && retries-- > 0) {
		k_msleep(1);
	}

	if (rx_chunks_mask != BIT_MASK(RX_CHUNK_CNT)) {
		rx_chunks_mask = BIT_MASK(RX_CHUNK_CNT);
	}
}

void async_rx_start(bool hwfc)
{
	uint8_t *buf = alloc_rx_chunk();
	int err;

	zassert_not_null(buf);
	err = uart_rx_enable(uart_dev, buf, RX_CHUNK_LEN, RX_TIMEOUT);
	if (err == -ENOTSUP) {
		/* The instance lacks what its driver's async mode needs, DMA
		 * channels for instance.
		 */
		ztest_test_skip();
	}
	zassert_equal(err, 0);
	k_msleep(hwfc ? 10 : 1);
}
#endif

void start_receiver(bool hwfc, enum uart_config_parity parity, bool two_stop_bits)
{
	receiver_shutdown();
	rx_active = true;
	uart_pair_configure(hwfc, parity, two_stop_bits);

#if IS_ENABLED(CONFIG_UART_INTERRUPT_DRIVEN)
#if IS_ENABLED(CONFIG_PM_DEVICE_RUNTIME)
	pm_device_runtime_get(uart_dev);
#endif
	uart_irq_err_enable(uart_dev);
	uart_irq_rx_enable(uart_dev);
#elif IS_ENABLED(CONFIG_UART_ASYNC_API)
	async_rx_start(hwfc);
#endif
}

void *test_setup(void)
{
	zassert_true(device_is_ready(uart_dev));
	zassert_true(device_is_ready(uart_dev_aux));

#if IS_ENABLED(CONFIG_UART_INTERRUPT_DRIVEN)
	zassert_equal(uart_irq_callback_set(uart_dev, dut_int_callback), 0);
#elif IS_ENABLED(CONFIG_UART_ASYNC_API)
	zassert_equal(uart_callback_set(uart_dev, dut_async_callback, NULL), 0);
#endif

	return NULL;
}

void test_before(void *fixture)
{
	ARG_UNUSED(fixture);
	reset_rx_state();
}

void test_after(void *fixture)
{
	ARG_UNUSED(fixture);
	receiver_shutdown();
}
```

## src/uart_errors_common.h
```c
/*
 * Copyright (c) 2024 Nordic Semiconductor ASA
 *
 * SPDX-License-Identifier: Apache-2.0
 */

#ifndef UART_ERRORS_COMMON_H_
#define UART_ERRORS_COMMON_H_

#include <stddef.h>
#include <stdint.h>

#include <zephyr/device.h>
#include <zephyr/drivers/uart.h>

extern const struct device *const uart_dev;
extern const struct device *const uart_dev_aux;

extern uint8_t rx_buffer[256];
extern uint32_t rx_buffer_cnt;
extern volatile uint32_t rx_stopped_cnt;
extern volatile uint32_t rx_parity_err_cnt;
extern volatile uint32_t rx_framing_err_cnt;
extern volatile bool rx_active;

void reset_rx_state(void);
void receiver_shutdown(void);
void start_receiver(bool hwfc, enum uart_config_parity parity, bool two_stop_bits);

void uart_pair_configure(bool hwfc, enum uart_config_parity parity, bool two_stop_bits);

void reconfigure(const struct device *dev, enum uart_config_parity parity, bool set_parity,
		 bool two_stop_bits, bool set_stop_bits, bool *hwfc);
void aux_tx(const struct device *dev, const uint8_t *buf, size_t len);

void *test_setup(void);
void test_before(void *fixture);
void test_after(void *fixture);

#if IS_ENABLED(CONFIG_UART_INTERRUPT_DRIVEN)
struct parity_error_tx_data {
	const uint8_t *buf;
	size_t len;
	size_t curr;
	int err_byte;
	struct k_sem *sem;
	bool cfg_ok;
};

void parity_error_tx_int_callback(const struct device *dev, void *user_data);
#endif

#if IS_ENABLED(CONFIG_UART_ASYNC_API)
void aux_async_callback(const struct device *dev, struct uart_event *evt, void *user_data);
void async_rx_reclaim_chunks(void);
void async_rx_start(bool hwfc);
#endif

#endif /* UART_ERRORS_COMMON_H_ */
```
